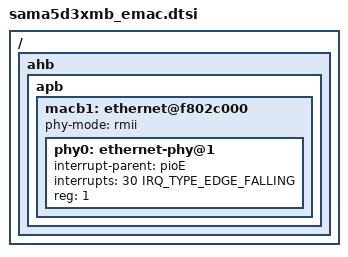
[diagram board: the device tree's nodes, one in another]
// SPDX-License-Identifier: GPL-2.0-or-later
/*
 * sama5d3xmb_emac.dts - Device Tree Include file for SAMA5D3x mother board
 * Ethernet
 *
 *  Copyright (C) 2016 Atmel,
 */

/ {
	ahb {
		apb {
			macb1: ethernet@f802c000 {
				phy-mode = "rmii";

				#address-cells = <1>;
				#size-cells = <0>;
				phy0: ethernet-phy@1 {
					interrupt-parent = <&pioE>;
					interrupts = <30 IRQ_TYPE_EDGE_FALLING>;
					reg = <1>;
				};
			};
		};
	};
};
